# ESP32-P4 register map
Vendor: ESPRESSIF SYSTEMS (SHANGHAI) CO., LTD.; Series: ESP32 P-Series; File version: 2
CPU: RV32IMAFC r0p0, little endian, no MPU, FPU, 0 interrupt priority bits
Address unit: 32 bits
Registers are 32-bit, read-write, reset 0x0 unless marked. A register's access mark holds for its fields unless they carry their own. Offsets are from the block's base; [hi:lo] are bit positions; {n}, {i} and the like mark numbered series.

## EFUSE — eFuse Controller
Base 0x5012D000
0x00 PGM_DATA0 — Register 0 that stores data to be programmed.
  [31:0] PGM_DATA_0 — Configures the 0th 32-bit data to be programmed.
0x04 PGM_DATA1 — Register 1 that stores data to be programmed.
  [31:0] PGM_DATA_1 — Configures the 1st 32-bit data to be programmed.
0x08 PGM_DATA2 — Register 2 that stores data to be programmed.
  [31:0] PGM_DATA_2 — Configures the 2nd 32-bit data to be programmed.
0x0C PGM_DATA3 — Register 3 that stores data to be programmed.
  [31:0] PGM_DATA_3 — Configures the 3rd 32-bit data to be programmed.
{0x0+4i} PGM_DATA{i} (i=4..7) — Register {i} that stores data to be programmed.
  [31:0] PGM_DATA_{i} — Configures the {i}th 32-bit data to be programmed.
0x20 PGM_CHECK_VALUE0 — Register 0 that stores the RS code to be programmed.
  [31:0] PGM_RS_DATA_0 — Configures the 0th 32-bit RS code to be programmed.
0x24 PGM_CHECK_VALUE1 — Register 1 that stores the RS code to be programmed.
  [31:0] PGM_RS_DATA_1 — Configures the 1st 32-bit RS code to be programmed.
0x28 PGM_CHECK_VALUE2 — Register 2 that stores the RS code to be programmed.
  [31:0] PGM_RS_DATA_2 — Configures the 2nd 32-bit RS code to be programmed.
0x2C RD_WR_DIS ro — BLOCK0 data register 0.
  [31:0] WR_DIS — Represents whether programming of individual eFuse memory bit is disabled or enabled. 1: Disabled. 0 Enabled.
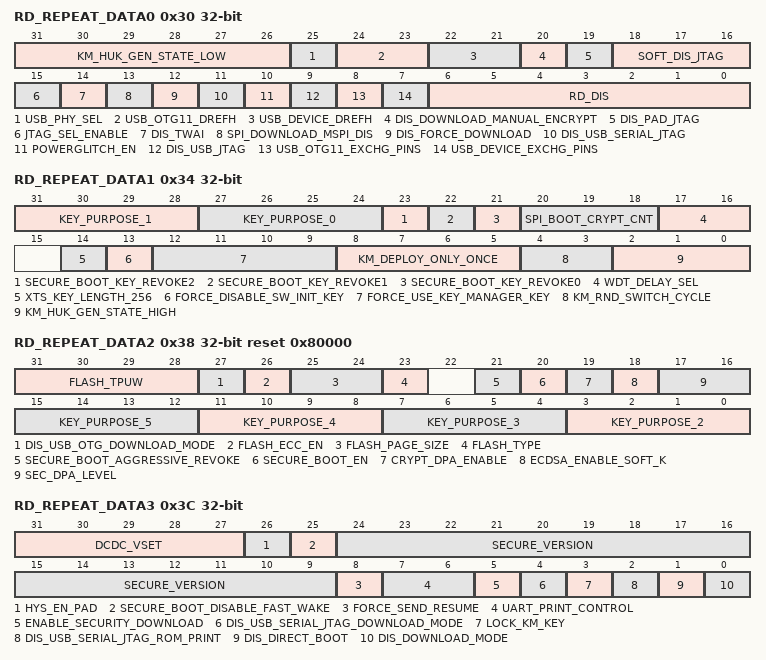
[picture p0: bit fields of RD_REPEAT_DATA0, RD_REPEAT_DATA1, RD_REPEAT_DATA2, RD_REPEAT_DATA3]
0x30 RD_REPEAT_DATA0 ro — BLOCK0 data register 1.
  [31:26] KM_HUK_GEN_STATE_LOW — Set this bit to control validation of HUK generate mode. Odd of 1 is invalid, even of 1 is valid.
  [25] USB_PHY_SEL
  [24:23] USB_OTG11_DREFH — USB intphy of usb otg11 signle-end input high threshold, 1.76V to 2V. Step by 80mV
  [22:21] USB_DEVICE_DREFH — USB intphy of usb device signle-end input high threshold, 1.76V to 2V. Step by 80mV
  [20] DIS_DOWNLOAD_MANUAL_ENCRYPT — Represents whether flash encrypt function is disabled or enabled(except in SPI boot mode). 1: disabled. 0: enabled.
  [19] DIS_PAD_JTAG — Represents whether JTAG is disabled in the hard way(permanently). 1: disabled. 0: enabled.
  [18:16] SOFT_DIS_JTAG — Represents whether JTAG is disabled in soft way. Odd number: disabled. Even number: enabled.
  [15] JTAG_SEL_ENABLE — Represents whether the selection between usb_to_jtag and pad_to_jtag through strapping gpio15 when both EFUSE_DIS_PAD_JTAG and EFUSE_DIS_USB_JTAG are equal to 0 is enabled or disabled. 1: enabled. 0: disabled.
  [14] DIS_TWAI — Represents whether TWAI function is disabled or enabled. 1: disabled. 0: enabled.
  [13] SPI_DOWNLOAD_MSPI_DIS — Set this bit to disable accessing MSPI flash/MSPI ram by SYS AXI matrix during boot_mode_download.
  [12] DIS_FORCE_DOWNLOAD — Represents whether the function that forces chip into download mode is disabled or enabled. 1: disabled. 0: enabled.
  [11] DIS_USB_SERIAL_JTAG — Represents whether USB-Serial-JTAG is disabled or enabled. 1: disabled. 0: enabled.
  [10] POWERGLITCH_EN — Represents whether power glitch function is enabled. 1: enabled. 0: disabled.
  [9] DIS_USB_JTAG — Represents whether the function of usb switch to jtag is disabled or enabled. 1: disabled. 0: enabled.
  [8] USB_OTG11_EXCHG_PINS — Enable usb otg11 exchange pins of D+ and D-.
  [7] USB_DEVICE_EXCHG_PINS — Enable usb device exchange pins of D+ and D-.
  [6:0] RD_DIS — Represents whether reading of individual eFuse block(block4~block10) is disabled or enabled. 1: disabled. 0: enabled.
0x34 RD_REPEAT_DATA1 ro — BLOCK0 data register 2.
  [31:28] KEY_PURPOSE_1 — Represents the purpose of Key1.
  [27:24] KEY_PURPOSE_0 — Represents the purpose of Key0.
  [23] SECURE_BOOT_KEY_REVOKE2 — Represents whether revoking third secure boot key is enabled or disabled. 1: enabled. 0: disabled.
  [22] SECURE_BOOT_KEY_REVOKE1 — Represents whether revoking second secure boot key is enabled or disabled. 1: enabled. 0: disabled.
  [21] SECURE_BOOT_KEY_REVOKE0 — Represents whether revoking first secure boot key is enabled or disabled. 1: enabled. 0: disabled.
  [20:18] SPI_BOOT_CRYPT_CNT — Represents whether SPI boot encrypt/decrypt is disabled or enabled. Odd number of 1: enabled. Even number of 1: disabled.
  [17:16] WDT_DELAY_SEL — Represents whether RTC watchdog timeout threshold is selected at startup. 1: selected. 0: not selected.
  [14] XTS_KEY_LENGTH_256 — Set this bit to configure flash encryption use xts-128 key, else use xts-256 key.
  [13] FORCE_DISABLE_SW_INIT_KEY — Set this bit to disable software written init key, and force use efuse_init_key.
  [12:9] FORCE_USE_KEY_MANAGER_KEY — Set each bit to control whether corresponding key must come from key manager.. 1 is true, 0 is false. Bit0: ecdsa. Bit1: xts. Bit2: hmac. Bit3: ds.
  [8:5] KM_DEPLOY_ONLY_ONCE — Set each bit to control whether corresponding key can only be deployed once. 1 is true, 0 is false. Bit0: ecdsa. Bit1: xts. Bit2: hmac. Bit3: ds.
  [4:3] KM_RND_SWITCH_CYCLE — Set bits to control key manager random number switch cycle. 0: control by register. 1: 8 km clk cycles. 2: 16 km cycles. 3: 32 km cycles.
  [2:0] KM_HUK_GEN_STATE_HIGH — Set this bit to control validation of HUK generate mode. Odd of 1 is invalid, even of 1 is valid.
0x38 RD_REPEAT_DATA2 ro reset 0x80000 — BLOCK0 data register 3.
  [31:28] FLASH_TPUW — Represents the flash waiting time after power-up, in unit of ms. When the value less than 15, the waiting time is the programmed value. Otherwise, the waiting time is 2 times the programmed value.
  [27] DIS_USB_OTG_DOWNLOAD_MODE — Set this bit to disable download via USB-OTG.
  [26] FLASH_ECC_EN — Set this bit to enable ecc for flash boot.
  [25:24] FLASH_PAGE_SIZE — Set flash page size.
  [23] FLASH_TYPE — The type of interfaced flash. 0: four data lines, 1: eight data lines.
  [21] SECURE_BOOT_AGGRESSIVE_REVOKE — Represents whether revoking aggressive secure boot is enabled or disabled. 1: enabled. 0: disabled.
  [20] SECURE_BOOT_EN — Represents whether secure boot is enabled or disabled. 1: enabled. 0: disabled.
  [19] CRYPT_DPA_ENABLE — Represents whether anti-dpa attack is enabled. 1:enabled. 0: disabled.
  [18] ECDSA_ENABLE_SOFT_K — Represents whether hardware random number k is forced used in ESDCA. 1: force used. 0: not force used.
  [17:16] SEC_DPA_LEVEL — Represents the spa secure level by configuring the clock random divide mode.
  [4n-5:4n-8] KEY_PURPOSE_{n} (n=2..5) — Represents the purpose of Key{n}.
0x3C RD_REPEAT_DATA3 ro — BLOCK0 data register 4.
  [31:27] DCDC_VSET — Set the dcdc voltage default.
  [26] HYS_EN_PAD — Represents whether the hysteresis function of corresponding PAD is enabled. 1: enabled. 0:disabled.
  [25] SECURE_BOOT_DISABLE_FAST_WAKE — Represents whether FAST VERIFY ON WAKE is disabled or enabled when Secure Boot is enabled. 1: disabled. 0: enabled.
  [24:9] SECURE_VERSION — Represents the version used by ESP-IDF anti-rollback feature.
  [8] FORCE_SEND_RESUME — Represents whether ROM code is forced to send a resume command during SPI boot. 1: forced. 0:not forced.
  [7:6] UART_PRINT_CONTROL — Represents the type of UART printing. 00: force enable printing. 01: enable printing when GPIO8 is reset at low level. 10: enable printing when GPIO8 is reset at high level. 11: force disable printing.
  [5] ENABLE_SECURITY_DOWNLOAD — Represents whether security download is enabled or disabled. 1: enabled. 0: disabled.
  [4] DIS_USB_SERIAL_JTAG_DOWNLOAD_MODE — Represents whether the USB-Serial-JTAG download function is disabled or enabled. 1: disabled. 0: enabled.
  [3] LOCK_KM_KEY
  [2] DIS_USB_SERIAL_JTAG_ROM_PRINT — Represents whether print from USB-Serial-JTAG is disabled or enabled. 1: disabled. 0: enabled.
  [1] DIS_DIRECT_BOOT — Represents whether direct boot mode is disabled or enabled. 1: disabled. 0: enabled.
  [0] DIS_DOWNLOAD_MODE — Represents whether Download mode is disabled or enabled. 1: disabled. 0: enabled.
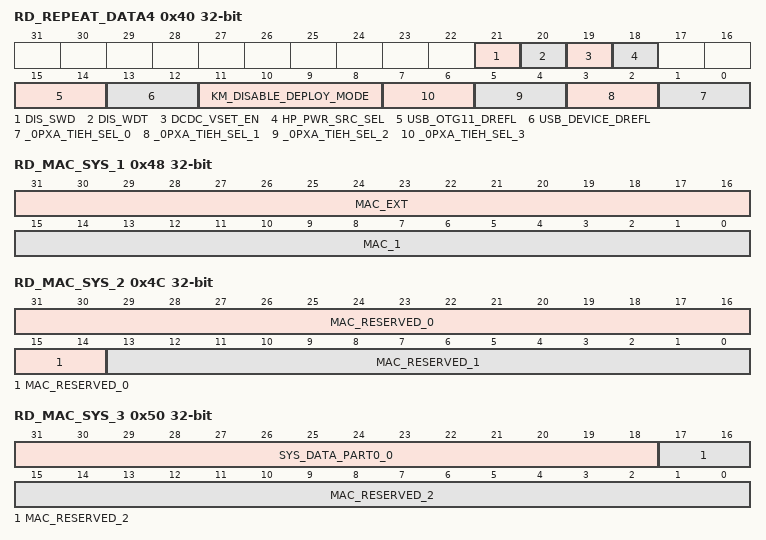
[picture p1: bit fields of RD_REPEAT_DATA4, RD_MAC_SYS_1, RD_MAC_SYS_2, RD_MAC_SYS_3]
0x40 RD_REPEAT_DATA4 ro — BLOCK0 data register 5.
  [21] DIS_SWD — Set this bit to disable super-watchdog.
  [20] DIS_WDT — Set this bit to disable watch dog.
  [19] DCDC_VSET_EN — Select dcdc vset use efuse_dcdc_vset.
  [18] HP_PWR_SRC_SEL — HP system power source select. 0:LDO. 1: DCDC.
  [15:14] USB_OTG11_DREFL — Represents the usb otg11 single-end input low threhold, 0.8 V to 1.04 V with step of 80 mV.
  [13:12] USB_DEVICE_DREFL — Represents the usb device single-end input low threhold, 0.8 V to 1.04 V with step of 80 mV.
  [11:8] KM_DISABLE_DEPLOY_MODE
  [2n+1:2n] _0PXA_TIEH_SEL_{n} (n=0..3)
0x44 RD_MAC_SYS_0 ro — BLOCK1 data register $n.
  [31:0] MAC_0 — Stores the low 32 bits of MAC address.
0x48 RD_MAC_SYS_1 ro — BLOCK1 data register $n.
  [31:16] MAC_EXT — Stores the extended bits of MAC address.
  [15:0] MAC_1 — Stores the high 16 bits of MAC address.
0x4C RD_MAC_SYS_2 ro — BLOCK1 data register $n.
  [31:14] MAC_RESERVED_0 — Reserved.
  [13:0] MAC_RESERVED_1 — Reserved.
0x50 RD_MAC_SYS_3 ro — BLOCK1 data register $n.
  [31:18] SYS_DATA_PART0_0 — Stores the first 14 bits of the zeroth part of system data.
  [17:0] MAC_RESERVED_2 — Reserved.
0x54 RD_MAC_SYS_4 ro — BLOCK1 data register $n.
  [31:0] SYS_DATA_PART0_1 — Stores the first 32 bits of the zeroth part of system data.
0x58 RD_MAC_SYS_5 ro — BLOCK1 data register $n.
  [31:0] SYS_DATA_PART0_2 — Stores the second 32 bits of the zeroth part of system data.
0x5C RD_SYS_PART1_DATA0 ro — Register $n of BLOCK2 (system).
  [31:0] SYS_DATA_PART1_0 — Stores the zeroth 32 bits of the first part of system data.
0x60 RD_SYS_PART1_DATA1 ro — Register $n of BLOCK2 (system).
  [31:0] SYS_DATA_PART1_1 — Stores the first 32 bits of the first part of system data.
0x64 RD_SYS_PART1_DATA2 ro — Register $n of BLOCK2 (system).
  [31:0] SYS_DATA_PART1_2 — Stores the second 32 bits of the first part of system data.
0x68 RD_SYS_PART1_DATA3 ro — Register $n of BLOCK2 (system).
  [31:0] SYS_DATA_PART1_3 — Stores the third 32 bits of the first part of system data.
0x6C RD_SYS_PART1_DATA4 ro — Register $n of BLOCK2 (system).
  [31:0] SYS_DATA_PART1_4 — Stores the fourth 32 bits of the first part of system data.
0x70 RD_SYS_PART1_DATA5 ro — Register $n of BLOCK2 (system).
  [31:0] SYS_DATA_PART1_5 — Stores the fifth 32 bits of the first part of system data.
0x74 RD_SYS_PART1_DATA6 ro — Register $n of BLOCK2 (system).
  [31:0] SYS_DATA_PART1_6 — Stores the sixth 32 bits of the first part of system data.
0x78 RD_SYS_PART1_DATA7 ro — Register $n of BLOCK2 (system).
  [31:0] SYS_DATA_PART1_7 — Stores the seventh 32 bits of the first part of system data.
0x7C RD_USR_DATA0 ro — Register $n of BLOCK3 (user).
  [31:0] USR_DATA0 — Stores the zeroth 32 bits of BLOCK3 (user).
0x80 RD_USR_DATA1 ro — Register $n of BLOCK3 (user).
  [31:0] USR_DATA1 — Stores the first 32 bits of BLOCK3 (user).
0x84 RD_USR_DATA2 ro — Register $n of BLOCK3 (user).
  [31:0] USR_DATA2 — Stores the second 32 bits of BLOCK3 (user).
0x88 RD_USR_DATA3 ro — Register $n of BLOCK3 (user).
  [31:0] USR_DATA3 — Stores the third 32 bits of BLOCK3 (user).
0x8C RD_USR_DATA4 ro — Register $n of BLOCK3 (user).
  [31:0] USR_DATA4 — Stores the fourth 32 bits of BLOCK3 (user).
0x90 RD_USR_DATA5 ro — Register $n of BLOCK3 (user).
  [31:0] USR_DATA5 — Stores the fifth 32 bits of BLOCK3 (user).
0x94 RD_USR_DATA6 ro — Register $n of BLOCK3 (user).
  [31:0] USR_DATA6 — Stores the sixth 32 bits of BLOCK3 (user).
0x98 RD_USR_DATA7 ro — Register $n of BLOCK3 (user).
  [31:0] USR_DATA7 — Stores the seventh 32 bits of BLOCK3 (user).
{0x9C+0x20*i} RD_KEY{i}_DATA0 ro (i=0..5) — Register $n of BLOCK{i+4} (KEY{i}).
  [31:0] KEY{i}_DATA0 — Stores the zeroth 32 bits of KEY{i}.
{0xA0+0x20*i} RD_KEY{i}_DATA1 ro (i=0..5) — Register $n of BLOCK{i+4} (KEY{i}).
  [31:0] KEY{i}_DATA1 — Stores the first 32 bits of KEY{i}.
{0xA4+0x20*i} RD_KEY{i}_DATA2 ro (i=0..5) — Register $n of BLOCK{i+4} (KEY{i}).
  [31:0] KEY{i}_DATA2 — Stores the second 32 bits of KEY{i}.
{0xA8+0x20*i} RD_KEY{i}_DATA3 ro (i=0..5) — Register $n of BLOCK{i+4} (KEY{i}).
  [31:0] KEY{i}_DATA3 — Stores the third 32 bits of KEY{i}.
{0xAC+0x20*i} RD_KEY{i}_DATA4 ro (i=0..5) — Register $n of BLOCK{i+4} (KEY{i}).
  [31:0] KEY{i}_DATA4 — Stores the fourth 32 bits of KEY{i}.
{0xB0+0x20*i} RD_KEY{i}_DATA5 ro (i=0..5) — Register $n of BLOCK{i+4} (KEY{i}).
  [31:0] KEY{i}_DATA5 — Stores the fifth 32 bits of KEY{i}.
{0xB4+0x20*i} RD_KEY{i}_DATA6 ro (i=0..5) — Register $n of BLOCK{i+4} (KEY{i}).
  [31:0] KEY{i}_DATA6 — Stores the sixth 32 bits of KEY{i}.
{0xB8+0x20*i} RD_KEY{i}_DATA7 ro (i=0..5) — Register $n of BLOCK{i+4} (KEY{i}).
  [31:0] KEY{i}_DATA7 — Stores the seventh 32 bits of KEY{i}.
0x15C RD_SYS_PART2_DATA0 ro — Register $n of BLOCK10 (system).
  [31:0] SYS_DATA_PART2_0 — Stores the 0th 32 bits of the 2nd part of system data.
0x160 RD_SYS_PART2_DATA1 ro — Register $n of BLOCK9 (KEY5).
  [31:0] SYS_DATA_PART2_1 — Stores the 0th 32 bits of the 2nd part of system data.
{0x15C+4i} RD_SYS_PART2_DATA{i} ro (i=2..7) — Register $n of BLOCK10 (system).
  [31:0] SYS_DATA_PART2_{i} — Stores the 0th 32 bits of the 2nd part of system data.
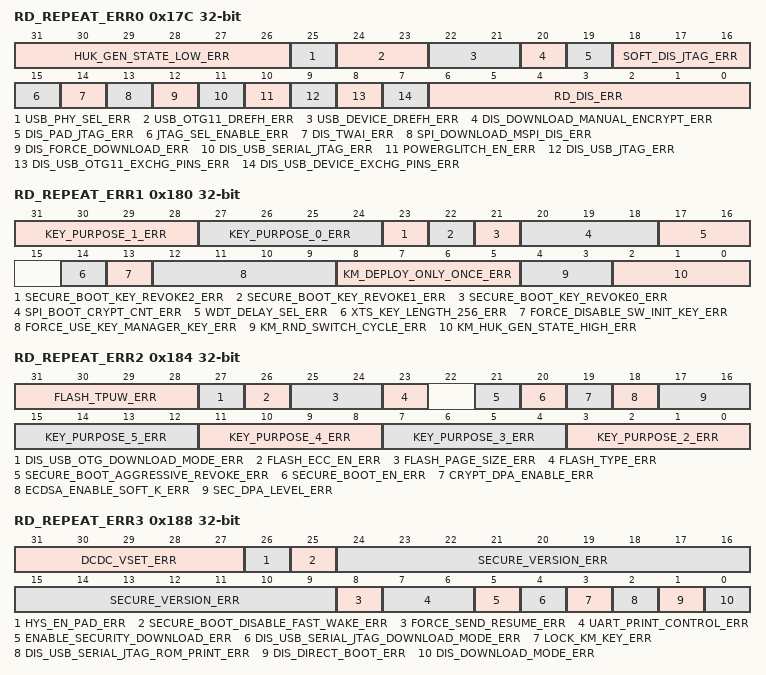
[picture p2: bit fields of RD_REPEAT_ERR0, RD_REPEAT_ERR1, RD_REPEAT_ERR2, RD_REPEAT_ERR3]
0x17C RD_REPEAT_ERR0 ro — Programming error record register 0 of BLOCK0.
  [31:26] HUK_GEN_STATE_LOW_ERR — Indicates a programming error of HUK_GEN_STATE_LOW.
  [25] USB_PHY_SEL_ERR — Indicates a programming error of USB_PHY_SEL.
  [24:23] USB_OTG11_DREFH_ERR — Indicates a programming error of USB_OTG11_DREFH.
  [22:21] USB_DEVICE_DREFH_ERR — Indicates a programming error of USB_DEVICE_DREFH.
  [20] DIS_DOWNLOAD_MANUAL_ENCRYPT_ERR — Indicates a programming error of DIS_DOWNLOAD_MANUAL_ENCRYPT.
  [19] DIS_PAD_JTAG_ERR — Indicates a programming error of DIS_PAD_JTAG.
  [18:16] SOFT_DIS_JTAG_ERR — Indicates a programming error of SOFT_DIS_JTAG.
  [15] JTAG_SEL_ENABLE_ERR — Indicates a programming error of JTAG_SEL_ENABLE.
  [14] DIS_TWAI_ERR — Indicates a programming error of DIS_TWAI.
  [13] SPI_DOWNLOAD_MSPI_DIS_ERR — Indicates a programming error of SPI_DOWNLOAD_MSPI_DIS.
  [12] DIS_FORCE_DOWNLOAD_ERR — Indicates a programming error of DIS_FORCE_DOWNLOAD.
  [11] DIS_USB_SERIAL_JTAG_ERR — Indicates a programming error of DIS_USB_SERIAL_JTAG.
  [10] POWERGLITCH_EN_ERR — Indicates a programming error of POWERGLITCH_EN.
  [9] DIS_USB_JTAG_ERR — Indicates a programming error of DIS_USB_JTAG.
  [8] DIS_USB_OTG11_EXCHG_PINS_ERR — Indicates a programming error of DIS_USB_OTG11_EXCHG_PINS.
  [7] DIS_USB_DEVICE_EXCHG_PINS_ERR — Indicates a programming error of DIS_USB_DEVICE_EXCHG_PINS.
  [6:0] RD_DIS_ERR — Indicates a programming error of RD_DIS.
0x180 RD_REPEAT_ERR1 ro — Programming error record register 1 of BLOCK0.
  [31:28] KEY_PURPOSE_1_ERR — Indicates a programming error of KEY_PURPOSE_1.
  [27:24] KEY_PURPOSE_0_ERR — Indicates a programming error of KEY_PURPOSE_0.
  [23] SECURE_BOOT_KEY_REVOKE2_ERR — Indicates a programming error of SECURE_BOOT_KEY_REVOKE2.
  [22] SECURE_BOOT_KEY_REVOKE1_ERR — Indicates a programming error of SECURE_BOOT_KEY_REVOKE1.
  [21] SECURE_BOOT_KEY_REVOKE0_ERR — Indicates a programming error of SECURE_BOOT_KEY_REVOKE0.
  [20:18] SPI_BOOT_CRYPT_CNT_ERR — Indicates a programming error of SPI_BOOT_CRYPT_CNT.
  [17:16] WDT_DELAY_SEL_ERR — Indicates a programming error of WDT_DELAY_SEL.
  [14] XTS_KEY_LENGTH_256_ERR — Indicates a programming error of XTS_KEY_LENGTH_256.
  [13] FORCE_DISABLE_SW_INIT_KEY_ERR — Indicates a programming error of FORCE_DISABLE_SW_INIT_KEY.
  [12:9] FORCE_USE_KEY_MANAGER_KEY_ERR — Indicates a programming error of FORCE_USE_KEY_MANAGER_KEY.
  [8:5] KM_DEPLOY_ONLY_ONCE_ERR — Indicates a programming error of KM_DEPLOY_ONLY_ONCE.
  [4:3] KM_RND_SWITCH_CYCLE_ERR — Indicates a programming error of KM_RND_SWITCH_CYCLE.
  [2:0] KM_HUK_GEN_STATE_HIGH_ERR — Indicates a programming error of HUK_GEN_STATE_HIGH.
0x184 RD_REPEAT_ERR2 ro — Programming error record register 2 of BLOCK0.
  [31:28] FLASH_TPUW_ERR — Indicates a programming error of FLASH_TPUW.
  [27] DIS_USB_OTG_DOWNLOAD_MODE_ERR — Indicates a programming error of DIS_USB_OTG_DOWNLOAD_MODE.
  [26] FLASH_ECC_EN_ERR — Indicates a programming error of FLASH_ECC_EN.
  [25:24] FLASH_PAGE_SIZE_ERR — Indicates a programming error of FLASH_PAGE_SIZE.
  [23] FLASH_TYPE_ERR — Indicates a programming error of FLASH_TYPE.
  [21] SECURE_BOOT_AGGRESSIVE_REVOKE_ERR — Indicates a programming error of SECURE_BOOT_AGGRESSIVE_REVOKE.
  [20] SECURE_BOOT_EN_ERR — Indicates a programming error of SECURE_BOOT_EN.
  [19] CRYPT_DPA_ENABLE_ERR — Indicates a programming error of CRYPT_DPA_ENABLE.
  [18] ECDSA_ENABLE_SOFT_K_ERR — Indicates a programming error of ECDSA_FORCE_USE_HARDWARE_K.
  [17:16] SEC_DPA_LEVEL_ERR — Indicates a programming error of SEC_DPA_LEVEL.
  [4n-5:4n-8] KEY_PURPOSE_{n}_ERR (n=2..5) — Indicates a programming error of KEY_PURPOSE_{n}.
0x188 RD_REPEAT_ERR3 ro — Programming error record register 3 of BLOCK0.
  [31:27] DCDC_VSET_ERR — Indicates a programming error of DCDC_VSET.
  [26] HYS_EN_PAD_ERR — Indicates a programming error of HYS_EN_PAD.
  [25] SECURE_BOOT_DISABLE_FAST_WAKE_ERR — Indicates a programming error of SECURE_BOOT_DISABLE_FAST_WAKE.
  [24:9] SECURE_VERSION_ERR — Indicates a programming error of SECURE VERSION.
  [8] FORCE_SEND_RESUME_ERR — Indicates a programming error of FORCE_SEND_RESUME.
  [7:6] UART_PRINT_CONTROL_ERR — Indicates a programming error of UART_PRINT_CONTROL.
  [5] ENABLE_SECURITY_DOWNLOAD_ERR — Indicates a programming error of ENABLE_SECURITY_DOWNLOAD.
  [4] DIS_USB_SERIAL_JTAG_DOWNLOAD_MODE_ERR — Indicates a programming error of DIS_USB_SERIAL_JTAG_DOWNLOAD_MODE.
  [3] LOCK_KM_KEY_ERR
  [2] DIS_USB_SERIAL_JTAG_ROM_PRINT_ERR — Indicates a programming error of DIS_USB_SERIAL_JTAG_ROM_PRINT_ERR.
  [1] DIS_DIRECT_BOOT_ERR — Indicates a programming error of DIS_DIRECT_BOOT.
  [0] DIS_DOWNLOAD_MODE_ERR — Indicates a programming error of DIS_DOWNLOAD_MODE.
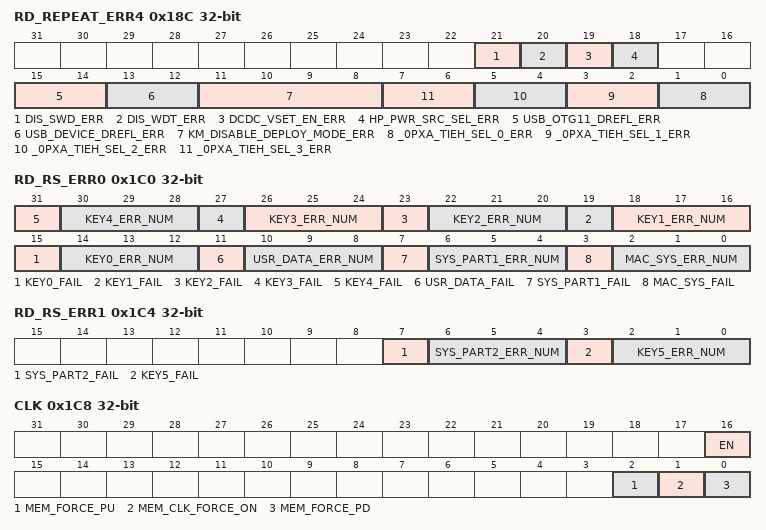
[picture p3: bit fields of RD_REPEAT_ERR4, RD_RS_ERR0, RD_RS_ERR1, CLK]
0x18C RD_REPEAT_ERR4 ro — Programming error record register 4 of BLOCK0.
  [21] DIS_SWD_ERR — Indicates a programming error of DIS_SWD.
  [20] DIS_WDT_ERR — Indicates a programming error of DIS_WDT.
  [19] DCDC_VSET_EN_ERR — Indicates a programming error of DCDC_VSET_EN.
  [18] HP_PWR_SRC_SEL_ERR — Indicates a programming error of HP_PWR_SRC_SEL.
  [15:14] USB_OTG11_DREFL_ERR — Indicates a programming error of USB_OTG11_DREFL.
  [13:12] USB_DEVICE_DREFL_ERR — Indicates a programming error of USB_DEVICE_DREFL.
  [11:8] KM_DISABLE_DEPLOY_MODE_ERR
  [2n+1:2n] _0PXA_TIEH_SEL_{n}_ERR (n=0..3) — Indicates a programming error of 0PXA_TIEH_SEL_{n}.
0x1C0 RD_RS_ERR0 ro — Programming error record register 0 of BLOCK1-10.
  [4n+15] KEY{n}_FAIL (n=0..4) — 0: Means no failure and that the data of key{n} is reliable 1: Means that programming key{n} failed and the number of error bytes is over 6.
  [4n+14:4n+12] KEY{n}_ERR_NUM (n=0..4) — The value of this signal means the number of error bytes.
  [11] USR_DATA_FAIL — 0: Means no failure and that the user data is reliable 1: Means that programming user data failed and the number of error bytes is over 6.
  [10:8] USR_DATA_ERR_NUM — The value of this signal means the number of error bytes.
  [7] SYS_PART1_FAIL — 0: Means no failure and that the data of system part1 is reliable 1: Means that programming user data failed and the number of error bytes is over 6.
  [6:4] SYS_PART1_ERR_NUM — The value of this signal means the number of error bytes.
  [3] MAC_SYS_FAIL — 0: Means no failure and that the data of MAC_SPI_8M is reliable 1: Means that programming user data failed and the number of error bytes is over 6.
  [2:0] MAC_SYS_ERR_NUM — The value of this signal means the number of error bytes.
0x1C4 RD_RS_ERR1 ro — Programming error record register 1 of BLOCK1-10.
  [7] SYS_PART2_FAIL — 0: Means no failure and that the data of system part2 is reliable 1: Means that programming user data failed and the number of error bytes is over 6.
  [6:4] SYS_PART2_ERR_NUM — The value of this signal means the number of error bytes.
  [3] KEY5_FAIL — 0: Means no failure and that the data of key5 is reliable 1: Means that programming key5 failed and the number of error bytes is over 6.
  [2:0] KEY5_ERR_NUM — The value of this signal means the number of error bytes.
0x1C8 CLK — eFuse clcok configuration register.
  [16] EN — Set this bit to force enable eFuse register configuration clock signal.
  [2] MEM_FORCE_PU — Set this bit to force eFuse SRAM into working mode.
  [1] MEM_CLK_FORCE_ON — Set this bit and force to activate clock signal of eFuse SRAM.
  [0] MEM_FORCE_PD — Set this bit to force eFuse SRAM into power-saving mode.
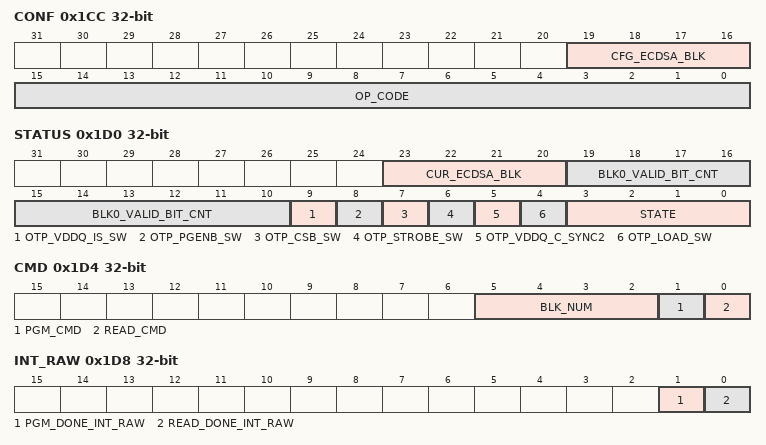
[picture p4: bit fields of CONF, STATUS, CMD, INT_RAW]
0x1CC CONF — eFuse operation mode configuraiton register
  [19:16] CFG_ECDSA_BLK — Configures which block to use for ECDSA key output.
  [15:0] OP_CODE — 0x5A5A: programming operation command 0x5AA5: read operation command.
0x1D0 STATUS ro — eFuse status register.
  [23:20] CUR_ECDSA_BLK — Indicates which block is used for ECDSA key output.
  [19:10] BLK0_VALID_BIT_CNT — Indicates the number of block valid bit.
  [9] OTP_VDDQ_IS_SW — The value of OTP_VDDQ_IS_SW.
  [8] OTP_PGENB_SW — The value of OTP_PGENB_SW.
  [7] OTP_CSB_SW — The value of OTP_CSB_SW.
  [6] OTP_STROBE_SW — The value of OTP_STROBE_SW.
  [5] OTP_VDDQ_C_SYNC2 — The value of OTP_VDDQ_C_SYNC2.
  [4] OTP_LOAD_SW — The value of OTP_LOAD_SW.
  [3:0] STATE — Indicates the state of the eFuse state machine.
0x1D4 CMD — eFuse command register.
  [5:2] BLK_NUM — The serial number of the block to be programmed. Value 0-10 corresponds to block number 0-10, respectively.
  [1] PGM_CMD — Set this bit to send programming command.
  [0] READ_CMD — Set this bit to send read command.
0x1D8 INT_RAW ro — eFuse raw interrupt register.
  [1] PGM_DONE_INT_RAW — The raw bit signal for pgm_done interrupt.
  [0] READ_DONE_INT_RAW — The raw bit signal for read_done interrupt.
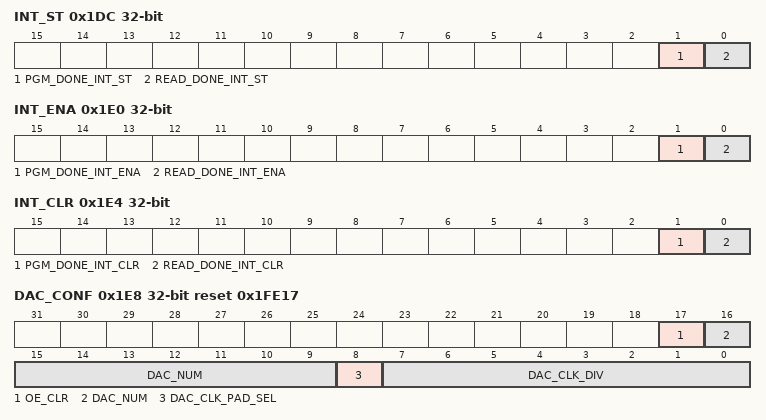
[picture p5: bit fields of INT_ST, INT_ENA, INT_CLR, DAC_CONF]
0x1DC INT_ST ro — eFuse interrupt status register.
  [1] PGM_DONE_INT_ST — The status signal for pgm_done interrupt.
  [0] READ_DONE_INT_ST — The status signal for read_done interrupt.
0x1E0 INT_ENA — eFuse interrupt enable register.
  [1] PGM_DONE_INT_ENA — The enable signal for pgm_done interrupt.
  [0] READ_DONE_INT_ENA — The enable signal for read_done interrupt.
0x1E4 INT_CLR wo — eFuse interrupt clear register.
  [1] PGM_DONE_INT_CLR — The clear signal for pgm_done interrupt.
  [0] READ_DONE_INT_CLR — The clear signal for read_done interrupt.
0x1E8 DAC_CONF reset 0x1FE17 — Controls the eFuse programming voltage.
  [17] OE_CLR — Reduces the power supply of the programming voltage.
  [16:9] DAC_NUM — Controls the rising period of the programming voltage.
  [8] DAC_CLK_PAD_SEL — Don't care.
  [7:0] DAC_CLK_DIV — Controls the division factor of the rising clock of the programming voltage.
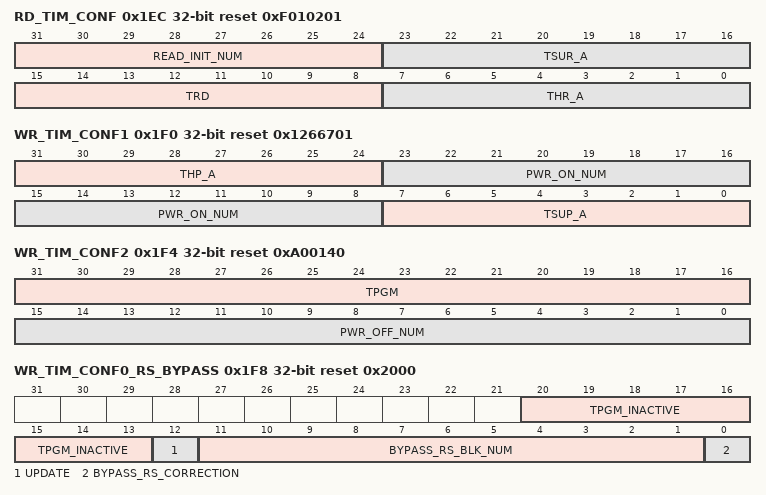
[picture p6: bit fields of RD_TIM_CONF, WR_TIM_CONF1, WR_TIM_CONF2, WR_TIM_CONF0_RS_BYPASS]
0x1EC RD_TIM_CONF reset 0xF010201 — Configures read timing parameters.
  [31:24] READ_INIT_NUM — Configures the waiting time of reading eFuse memory.
  [23:16] TSUR_A — Configures the read setup time.
  [15:8] TRD — Configures the read time.
  [7:0] THR_A — Configures the read hold time.
0x1F0 WR_TIM_CONF1 reset 0x1266701 — Configurarion register 1 of eFuse programming timing parameters.
  [31:24] THP_A — Configures the programming hold time.
  [23:8] PWR_ON_NUM — Configures the power up time for VDDQ.
  [7:0] TSUP_A — Configures the programming setup time.
0x1F4 WR_TIM_CONF2 reset 0xA00140 — Configurarion register 2 of eFuse programming timing parameters.
  [31:16] TPGM — Configures the active programming time.
  [15:0] PWR_OFF_NUM — Configures the power outage time for VDDQ.
0x1F8 WR_TIM_CONF0_RS_BYPASS access per field reset 0x2000 — Configurarion register0 of eFuse programming time parameters and rs bypass operation.
  [20:13] TPGM_INACTIVE rw — Configures the inactive programming time.
  [12] UPDATE wo — Set this bit to update multi-bit register signals.
  [11:1] BYPASS_RS_BLK_NUM rw — Configures block number of programming twice operation.
  [0] BYPASS_RS_CORRECTION rw — Set this bit to bypass reed solomon correction step.
0x1FC DATE reset 0x2305050 — eFuse version register.
  [27:0] DATE — Stores eFuse version.
0x800 APB2OTP_WR_DIS ro — eFuse apb2otp block0 data register1.
  [31:0] APB2OTP_BLOCK0_WR_DIS — Otp block0 write disable data.
{0x800+4i} APB2OTP_BLK0_BACKUP1_W{i} ro (i=1..5) — eFuse apb2otp block0 data register{i+1}.
  [31:0] APB2OTP_BLOCK0_BACKUP1_W{i} — Otp block0 backup1 word{i} data.
{0x814+4i} APB2OTP_BLK0_BACKUP2_W{i} ro (i=1..5) — eFuse apb2otp block0 data register{i+6}.
  [31:0] APB2OTP_BLOCK0_BACKUP2_W{i} — Otp block0 backup2 word{i} data.
{0x828+4i} APB2OTP_BLK0_BACKUP3_W{i} ro (i=1..5) — eFuse apb2otp block0 data register{i+11}.
  [31:0] APB2OTP_BLOCK0_BACKUP3_W{i} — Otp block0 backup3 word{i} data.
{0x83C+4i} APB2OTP_BLK0_BACKUP4_W{i} ro (i=1..5) — eFuse apb2otp block0 data register{i+16}.
  [31:0] APB2OTP_BLOCK0_BACKUP4_W{i} — Otp block0 backup4 word{i} data.
{0x850+4i} APB2OTP_BLK1_W{i} ro (i=1..9) — eFuse apb2otp block1 data register{i}.
  [31:0] APB2OTP_BLOCK1_W{i} — Otp block1 word{i} data.
{0x874+4i} APB2OTP_BLK2_W{i} ro (i=1..11) — eFuse apb2otp block2 data register{i}.
  [31:0] APB2OTP_BLOCK2_W{i} — Otp block2 word{i} data.
{0x8A0+4i} APB2OTP_BLK3_W{i} ro (i=1..11) — eFuse apb2otp block3 data register{i}.
  [31:0] APB2OTP_BLOCK3_W{i} — Otp block3 word{i} data.
{0x8CC+4i} APB2OTP_BLK4_W{i} ro (i=1..9) — eFuse apb2otp block4 data register{i}.
  [31:0] APB2OTP_BLOCK4_W{i} — Otp block4 word{i} data.
0x8F4 APB2OTP_BLK4_W10 ro — eFuse apb2otp block4 data registe10.
  [31:0] APB2OTP_BLOCK4_W10 — Otp block4 word10 data.
0x8F8 APB2OTP_BLK4_W11 ro — eFuse apb2otp block4 data register11.
  [31:0] APB2OTP_BLOCK4_W11 — Otp block4 word11 data.
{0x8F8+4i} APB2OTP_BLK5_W{i} ro (i=1..11) — eFuse apb2otp block5 data register{i}.
  [31:0] APB2OTP_BLOCK5_W{i} — Otp block5 word{i} data.
{0x924+4i} APB2OTP_BLK6_W{i} ro (i=1..11) — eFuse apb2otp block6 data register{i}.
  [31:0] APB2OTP_BLOCK6_W{i} — Otp block6 word{i} data.
{0x950+4i} APB2OTP_BLK7_W{i} ro (i=1..11) — eFuse apb2otp block7 data register{i}.
  [31:0] APB2OTP_BLOCK7_W{i} — Otp block7 word{i} data.
{0x97C+4i} APB2OTP_BLK8_W{i} ro (i=1..11) — eFuse apb2otp block8 data register{i}.
  [31:0] APB2OTP_BLOCK8_W{i} — Otp block8 word{i} data.
{0x9A8+4i} APB2OTP_BLK9_W{i} ro (i=1..11) — eFuse apb2otp block9 data register{i}.
  [31:0] APB2OTP_BLOCK9_W{i} — Otp block9 word{i} data.
{0x9D4+4i} APB2OTP_BLK10_W{i} ro (i=1..9) — eFuse apb2otp block10 data register{i}.
  [31:0] APB2OTP_BLOCK10_W{i} — Otp block10 word{i} data.
0x9FC APB2OTP_BLK10_W10 ro — eFuse apb2otp block10 data register10.
  [31:0] APB2OTP_BLOCK19_W10 — Otp block10 word10 data.
0xA00 APB2OTP_BLK10_W11 ro — eFuse apb2otp block10 data register11.
  [31:0] APB2OTP_BLOCK10_W11 — Otp block10 word11 data.
0xA08 APB2OTP_EN — eFuse apb2otp enable configuration register.
  [0] APB2OTP_APB2OTP_EN — Apb2otp mode enable signal.
